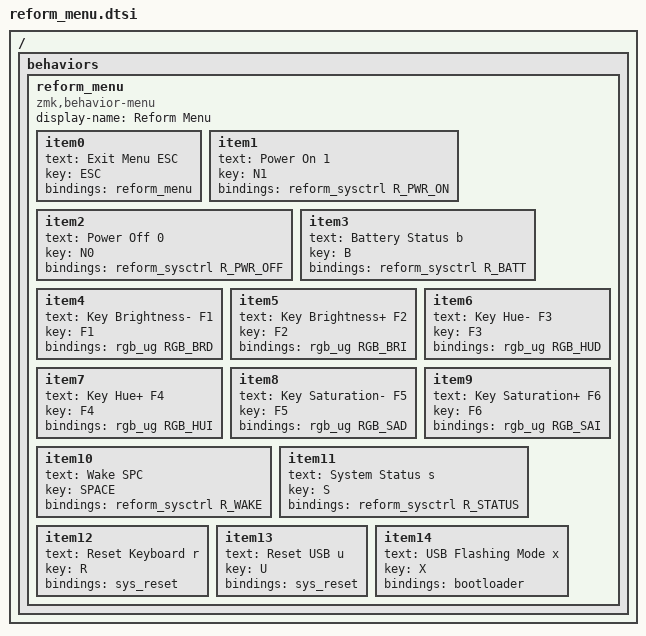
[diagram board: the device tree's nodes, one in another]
/*
  SPDX-License-Identifier: GPL-3.0-or-later
  Copyright 2026 joguSD
*/
#include <behaviors.dtsi>
#include <dt-bindings/zmk/behaviors.h>
#include <dt-bindings/zmk/keys.h>
#include <dt-bindings/zmk/reform_sysctrl.h>
#include <dt-bindings/zmk/rgb.h>

/ {
  behaviors {
    /omit-if-no-ref/
    reform_menu: reform_menu {
      compatible = "zmk,behavior-menu";
      #binding-cells = <0>;
      display-name = "Reform Menu";

      item0 {
        text = "Exit Menu         ESC";
        key = <ESC>;
        bindings = <&reform_menu>;
      };
      item1 {
        text = "Power On            1";
        key = <N1>;
        bindings = <&reform_sysctrl R_PWR_ON>;
      };
      item2 {
        text = "Power Off           0";
        key = <N0>;
        bindings = <&reform_sysctrl R_PWR_OFF>;
      };
      item3 {
        text = "Battery Status      b";
        key = <B>;
        bindings = <&reform_sysctrl R_BATT>;
      };
      item4 {
        text = "Key Brightness-    F1";
        key = <F1>;
        bindings = <&rgb_ug RGB_BRD>;
      };
      item5 {
        text = "Key Brightness+    F2";
        key = <F2>;
        bindings = <&rgb_ug RGB_BRI>;
      };
      item6 {
        text = "Key Hue-           F3";
        key = <F3>;
        bindings = <&rgb_ug RGB_HUD>;
      };
      item7 {
        text = "Key Hue+           F4";
        key = <F4>;
        bindings = <&rgb_ug RGB_HUI>;
      };
      item8 {
        text = "Key Saturation-    F5";
        key = <F5>;
        bindings = <&rgb_ug RGB_SAD>;
      };
      item9 {
        text = "Key Saturation+    F6";
        key = <F6>;
        bindings = <&rgb_ug RGB_SAI>;
      };
      item10 {
        text = "Wake              SPC";
        key = <SPACE>;
        bindings = <&reform_sysctrl R_WAKE>;
      };
      item11 {
        text = "System Status       s";
        key = <S>;
        bindings = <&reform_sysctrl R_STATUS>;
      };
      item12 {
        text = "Reset Keyboard      r";
        key = <R>;
        bindings = <&sys_reset>;
      };
      item13 {
        text = "Reset USB           u";
        key = <U>;
        bindings = <&sys_reset>;
      };
      item14 {
        text = "USB Flashing Mode   x";
        key = <X>;
        bindings = <&bootloader>;
      };
    };
  };
};
